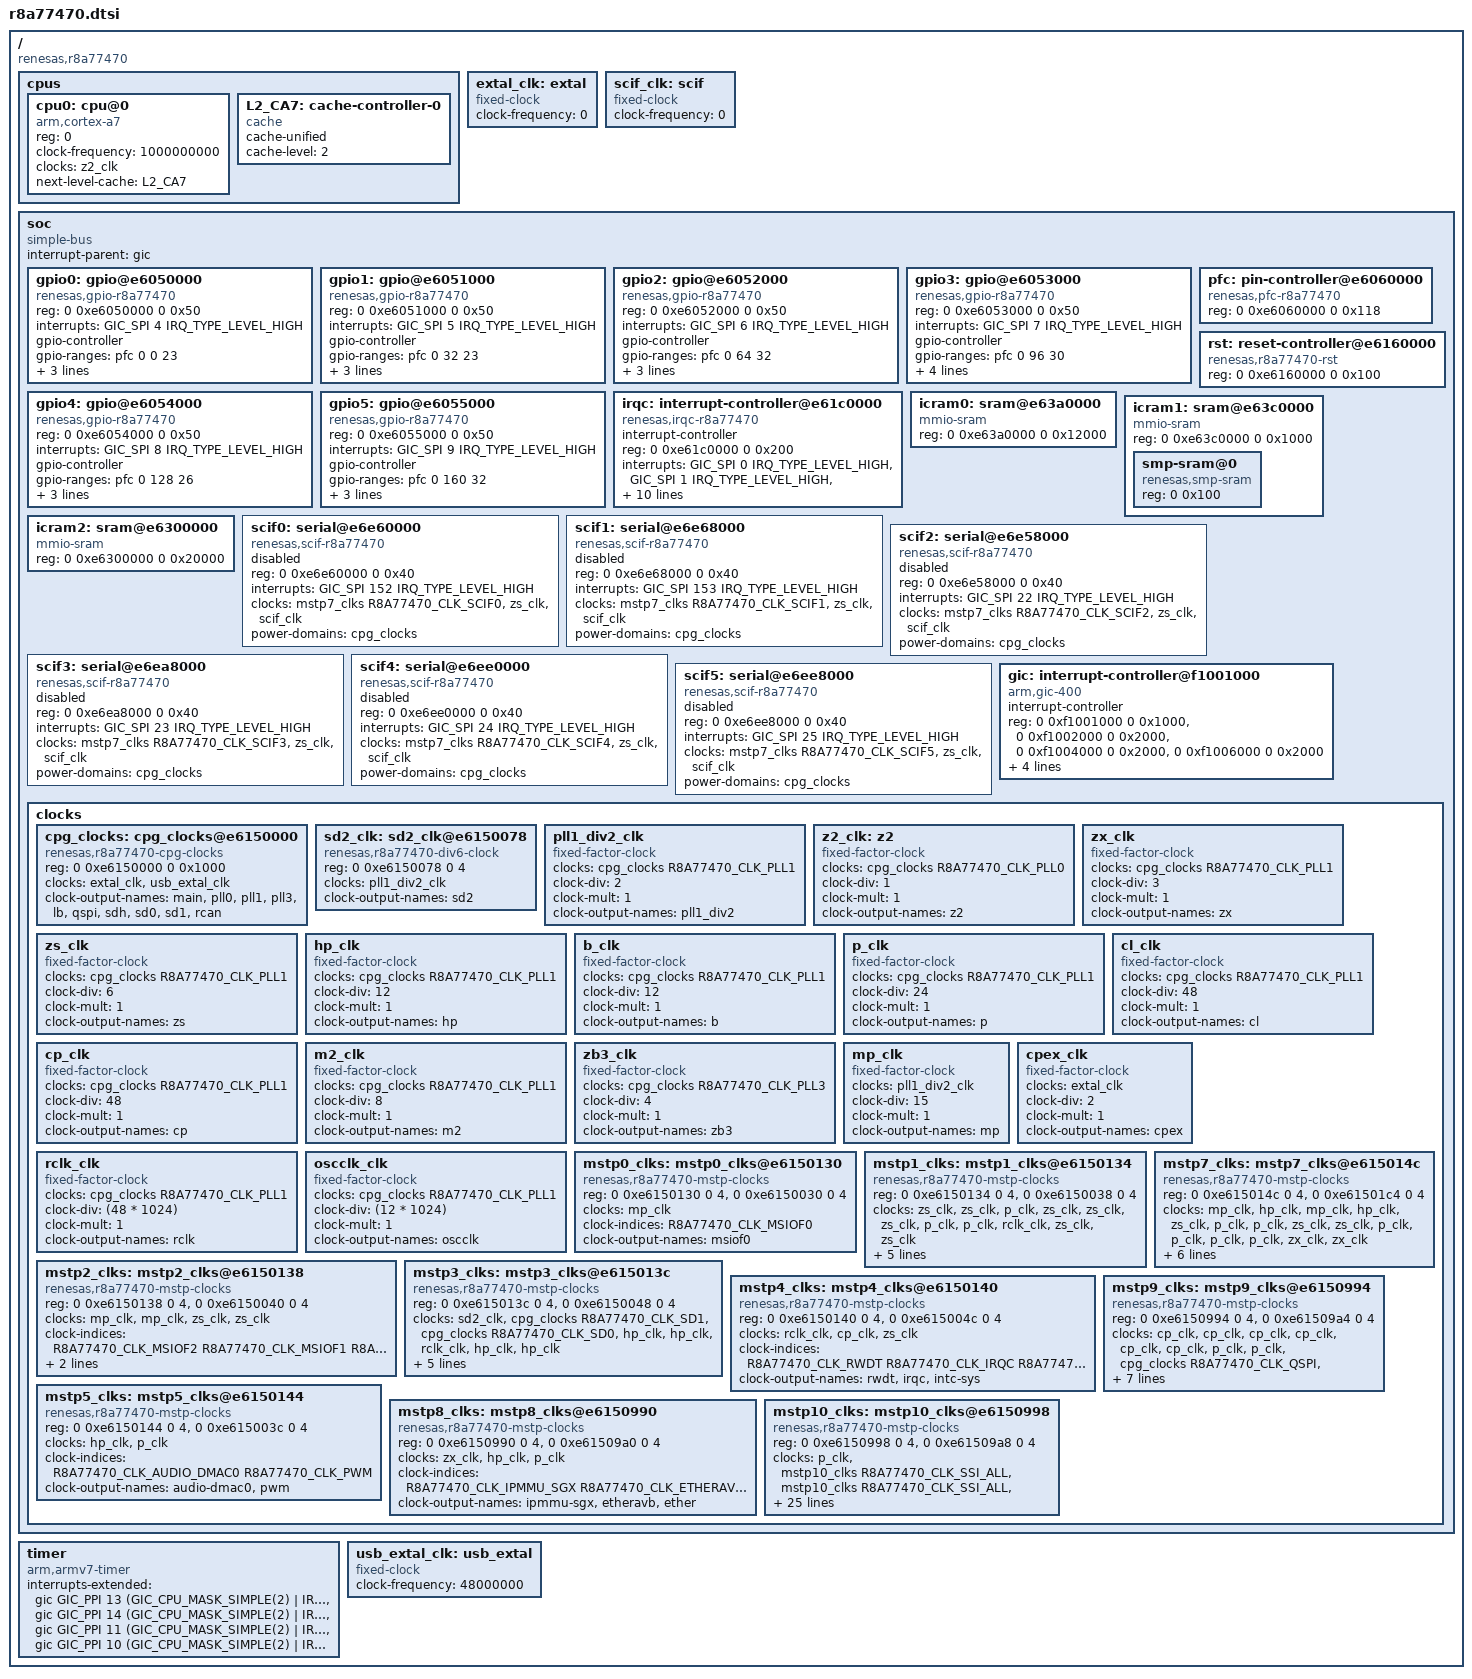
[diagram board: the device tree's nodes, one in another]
// SPDX-License-Identifier: GPL-2.0
/*
 * Device Tree Source for the r8a77470 SoC
 *
 * Copyright (C) 2018 Renesas Electronics Corp.
 */

#include <dt-bindings/interrupt-controller/irq.h>
#include <dt-bindings/interrupt-controller/arm-gic.h>
#include <dt-bindings/clock/r8a77470-clock.h>

/ {
	compatible = "renesas,r8a77470";
	#address-cells = <2>;
	#size-cells = <2>;

	cpus {
		#address-cells = <1>;
		#size-cells = <0>;

		cpu0: cpu@0 {
			device_type = "cpu";
			compatible = "arm,cortex-a7";
			reg = <0>;
			clock-frequency = <1000000000>;
			clocks = <&z2_clk>;
			next-level-cache = <&L2_CA7>;
		};


		L2_CA7: cache-controller-0 {
			compatible = "cache";
			cache-unified;
			cache-level = <2>;
		};
	};

	/* External root clock */
	extal_clk: extal {
		compatible = "fixed-clock";
		#clock-cells = <0>;
		/* This value must be overridden by the board. */
		clock-frequency = <0>;
	};

	/* External SCIF clock */
	scif_clk: scif {
		compatible = "fixed-clock";
		#clock-cells = <0>;
		/* This value must be overridden by the board. */
		clock-frequency = <0>;
	};

	soc {
		compatible = "simple-bus";
		interrupt-parent = <&gic>;

		#address-cells = <2>;
		#size-cells = <2>;
		ranges;

		gpio0: gpio@e6050000 {
			compatible = "renesas,gpio-r8a77470",
				     "renesas,rcar-gen2-gpio";
			reg = <0 0xe6050000 0 0x50>;
			interrupts = <GIC_SPI 4 IRQ_TYPE_LEVEL_HIGH>;
			#gpio-cells = <2>;
			gpio-controller;
			gpio-ranges = <&pfc 0 0 23>;
			#interrupt-cells = <2>;
			interrupt-controller;
			clocks = <&mstp9_clks R8A77470_CLK_GPIO0>;
			power-domains = <&cpg_clocks>;
		};

		gpio1: gpio@e6051000 {
			compatible = "renesas,gpio-r8a77470",
				     "renesas,rcar-gen2-gpio";
			reg = <0 0xe6051000 0 0x50>;
			interrupts = <GIC_SPI 5 IRQ_TYPE_LEVEL_HIGH>;
			#gpio-cells = <2>;
			gpio-controller;
			gpio-ranges = <&pfc 0 32 23>;
			#interrupt-cells = <2>;
			interrupt-controller;
			clocks = <&mstp9_clks R8A77470_CLK_GPIO1>;
			power-domains = <&cpg_clocks>;
		};

		gpio2: gpio@e6052000 {
			compatible = "renesas,gpio-r8a77470",
				     "renesas,rcar-gen2-gpio";
			reg = <0 0xe6052000 0 0x50>;
			interrupts = <GIC_SPI 6 IRQ_TYPE_LEVEL_HIGH>;
			#gpio-cells = <2>;
			gpio-controller;
			gpio-ranges = <&pfc 0 64 32>;
			#interrupt-cells = <2>;
			interrupt-controller;
			clocks = <&mstp9_clks R8A77470_CLK_GPIO2>;
			power-domains = <&cpg_clocks>;
		};

		gpio3: gpio@e6053000 {
			compatible = "renesas,gpio-r8a77470",
				     "renesas,rcar-gen2-gpio";
			reg = <0 0xe6053000 0 0x50>;
			interrupts = <GIC_SPI 7 IRQ_TYPE_LEVEL_HIGH>;
			#gpio-cells = <2>;
			gpio-controller;
			gpio-ranges = <&pfc 0 96 30>;
			gpio-reserved-ranges = <17 10>;
			#interrupt-cells = <2>;
			interrupt-controller;
			clocks = <&mstp9_clks R8A77470_CLK_GPIO3>;
			power-domains = <&cpg_clocks>;
		};

		gpio4: gpio@e6054000 {
			compatible = "renesas,gpio-r8a77470",
				     "renesas,rcar-gen2-gpio";
			reg = <0 0xe6054000 0 0x50>;
			interrupts = <GIC_SPI 8 IRQ_TYPE_LEVEL_HIGH>;
			#gpio-cells = <2>;
			gpio-controller;
			gpio-ranges = <&pfc 0 128 26>;
			#interrupt-cells = <2>;
			interrupt-controller;
			clocks = <&mstp9_clks R8A77470_CLK_GPIO4>;
			power-domains = <&cpg_clocks>;
		};

		gpio5: gpio@e6055000 {
			compatible = "renesas,gpio-r8a77470",
				     "renesas,rcar-gen2-gpio";
			reg = <0 0xe6055000 0 0x50>;
			interrupts = <GIC_SPI 9 IRQ_TYPE_LEVEL_HIGH>;
			#gpio-cells = <2>;
			gpio-controller;
			gpio-ranges = <&pfc 0 160 32>;
			#interrupt-cells = <2>;
			interrupt-controller;
			clocks = <&mstp9_clks R8A77470_CLK_GPIO5>;
			power-domains = <&cpg_clocks>;
		};

		pfc: pin-controller@e6060000 {
			compatible = "renesas,pfc-r8a77470";
			reg = <0 0xe6060000 0 0x118>;
		};

		rst: reset-controller@e6160000 {
			compatible = "renesas,r8a77470-rst";
			reg = <0 0xe6160000 0 0x100>;
		};

		irqc: interrupt-controller@e61c0000 {
			compatible = "renesas,irqc-r8a77470", "renesas,irqc";
			#interrupt-cells = <2>;
			interrupt-controller;
			reg = <0 0xe61c0000 0 0x200>;
			interrupts = <GIC_SPI 0 IRQ_TYPE_LEVEL_HIGH>,
				     <GIC_SPI 1 IRQ_TYPE_LEVEL_HIGH>,
				     <GIC_SPI 2 IRQ_TYPE_LEVEL_HIGH>,
				     <GIC_SPI 3 IRQ_TYPE_LEVEL_HIGH>,
				     <GIC_SPI 12 IRQ_TYPE_LEVEL_HIGH>,
				     <GIC_SPI 13 IRQ_TYPE_LEVEL_HIGH>,
				     <GIC_SPI 14 IRQ_TYPE_LEVEL_HIGH>,
				     <GIC_SPI 15 IRQ_TYPE_LEVEL_HIGH>,
				     <GIC_SPI 16 IRQ_TYPE_LEVEL_HIGH>,
				     <GIC_SPI 17 IRQ_TYPE_LEVEL_HIGH>;
			clocks = <&mstp4_clks R8A77470_CLK_IRQC>;
			power-domains = <&cpg_clocks>;
		};

		icram0:	sram@e63a0000 {
			compatible = "mmio-sram";
			reg = <0 0xe63a0000 0 0x12000>;
		};

		icram1:	sram@e63c0000 {
			compatible = "mmio-sram";
			reg = <0 0xe63c0000 0 0x1000>;
			#address-cells = <1>;
			#size-cells = <1>;
			ranges = <0 0 0xe63c0000 0x1000>;

			smp-sram@0 {
				compatible = "renesas,smp-sram";
				reg = <0 0x100>;
			};
		};

		icram2:	sram@e6300000 {
			compatible = "mmio-sram";
			reg = <0 0xe6300000 0 0x20000>;
		};

		scif0: serial@e6e60000 {
			compatible = "renesas,scif-r8a77470", "renesas,scif";
			reg = <0 0xe6e60000 0 0x40>;
			interrupts = <GIC_SPI 152 IRQ_TYPE_LEVEL_HIGH>;
			clocks = <&mstp7_clks R8A77470_CLK_SCIF0>,
				 <&zs_clk>, <&scif_clk>;
			clock-names = "sci_ick", "brg_int", "scif_clk";
			power-domains = <&cpg_clocks>;
			status = "disabled";
		};

		scif1: serial@e6e68000 {
			compatible = "renesas,scif-r8a77470", "renesas,scif";
			reg = <0 0xe6e68000 0 0x40>;
			interrupts = <GIC_SPI 153 IRQ_TYPE_LEVEL_HIGH>;
			clocks = <&mstp7_clks R8A77470_CLK_SCIF1>,
				 <&zs_clk>, <&scif_clk>;
			clock-names = "sci_ick", "brg_int", "scif_clk";
			power-domains = <&cpg_clocks>;
			status = "disabled";
		};

		scif2: serial@e6e58000 {
			compatible = "renesas,scif-r8a77470", "renesas,scif";
			reg = <0 0xe6e58000 0 0x40>;
			interrupts = <GIC_SPI 22 IRQ_TYPE_LEVEL_HIGH>;
			clocks = <&mstp7_clks R8A77470_CLK_SCIF2>,
				 <&zs_clk>, <&scif_clk>;
			clock-names = "sci_ick", "brg_int", "scif_clk";
			power-domains = <&cpg_clocks>;
			status = "disabled";
		};

		scif3: serial@e6ea8000 {
			compatible = "renesas,scif-r8a77470", "renesas,scif";
			reg = <0 0xe6ea8000 0 0x40>;
			interrupts = <GIC_SPI 23 IRQ_TYPE_LEVEL_HIGH>;
			clocks = <&mstp7_clks R8A77470_CLK_SCIF3>,
				 <&zs_clk>, <&scif_clk>;
			clock-names = "sci_ick", "brg_int", "scif_clk";
			power-domains = <&cpg_clocks>;
			status = "disabled";
		};

		scif4: serial@e6ee0000 {
			compatible = "renesas,scif-r8a77470", "renesas,scif";
			reg = <0 0xe6ee0000 0 0x40>;
			interrupts = <GIC_SPI 24 IRQ_TYPE_LEVEL_HIGH>;
			clocks = <&mstp7_clks R8A77470_CLK_SCIF4>,
				 <&zs_clk>, <&scif_clk>;
			clock-names = "sci_ick", "brg_int", "scif_clk";
			power-domains = <&cpg_clocks>;
			status = "disabled";
		};

		scif5: serial@e6ee8000 {
			compatible = "renesas,scif-r8a77470",
				     "renesas,rcar-gen2-scif", "renesas,scif";
			reg = <0 0xe6ee8000 0 0x40>;
			interrupts = <GIC_SPI 25 IRQ_TYPE_LEVEL_HIGH>;
			clocks = <&mstp7_clks R8A77470_CLK_SCIF5>,
				 <&zs_clk>, <&scif_clk>;
			clock-names = "sci_ick", "brg_int", "scif_clk";
			power-domains = <&cpg_clocks>;
			status = "disabled";
		};

		gic: interrupt-controller@f1001000 {
			compatible = "arm,gic-400";
			#interrupt-cells = <3>;
			#address-cells = <0>;
			interrupt-controller;
			reg = <0 0xf1001000 0 0x1000>, <0 0xf1002000 0 0x2000>,
			      <0 0xf1004000 0 0x2000>, <0 0xf1006000 0 0x2000>;
			interrupts = <GIC_PPI 9 (GIC_CPU_MASK_SIMPLE(2) | IRQ_TYPE_LEVEL_HIGH)>;
			clocks = <&mstp4_clks R8A77470_CLK_INTC_SYS>;
			clock-names = "clk";
			power-domains = <&cpg_clocks>;
		};

		clocks {
			#address-cells = <2>;
			#size-cells = <2>;
			ranges;

			/* Special CPG clocks */
			cpg_clocks: cpg_clocks@e6150000 {
				compatible = "renesas,r8a77470-cpg-clocks",
					     "renesas,rcar-gen2-cpg-clocks";
				reg = <0 0xe6150000 0 0x1000>;
				clocks = <&extal_clk &usb_extal_clk>;
				#clock-cells = <1>;
				clock-output-names = "main", "pll0", "pll1",
						     "pll3", "lb", "qspi",
						     "sdh", "sd0", "sd1",
						     "rcan";
				#power-domain-cells = <0>;
			};

			/* Variable factor clocks */
			sd2_clk: sd2_clk@e6150078 {
				compatible = "renesas,r8a77470-div6-clock",
					     "renesas,cpg-div6-clock";
				reg = <0 0xe6150078 0 4>;
				clocks = <&pll1_div2_clk>;
				#clock-cells = <0>;
				clock-output-names = "sd2";
			};

			/* Fixed factor clocks */
			pll1_div2_clk: pll1_div2_clk {
				compatible = "fixed-factor-clock";
				clocks = <&cpg_clocks R8A77470_CLK_PLL1>;
				#clock-cells = <0>;
				clock-div = <2>;
				clock-mult = <1>;
				clock-output-names = "pll1_div2";
			};
			z2_clk: z2 {
				compatible = "fixed-factor-clock";
				clocks = <&cpg_clocks R8A77470_CLK_PLL0>;
				#clock-cells = <0>;
				clock-div = <1>;
				clock-mult = <1>;
				clock-output-names = "z2";
			};
			zx_clk: zx_clk {
				compatible = "fixed-factor-clock";
				clocks = <&cpg_clocks R8A77470_CLK_PLL1>;
				#clock-cells = <0>;
				clock-div = <3>;
				clock-mult = <1>;
				clock-output-names = "zx";
			};
			zs_clk: zs_clk {
				compatible = "fixed-factor-clock";
				clocks = <&cpg_clocks R8A77470_CLK_PLL1>;
				#clock-cells = <0>;
				clock-div = <6>;
				clock-mult = <1>;
				clock-output-names = "zs";
			};
			hp_clk: hp_clk {
				compatible = "fixed-factor-clock";
				clocks = <&cpg_clocks R8A77470_CLK_PLL1>;
				#clock-cells = <0>;
				clock-div = <12>;
				clock-mult = <1>;
				clock-output-names = "hp";
			};
			b_clk: b_clk {
				compatible = "fixed-factor-clock";
				clocks = <&cpg_clocks R8A77470_CLK_PLL1>;
				#clock-cells = <0>;
				clock-div = <12>;
				clock-mult = <1>;
				clock-output-names = "b";
			};
			p_clk: p_clk {
				compatible = "fixed-factor-clock";
				clocks = <&cpg_clocks R8A77470_CLK_PLL1>;
				#clock-cells = <0>;
				clock-div = <24>;
				clock-mult = <1>;
				clock-output-names = "p";
			};
			cl_clk: cl_clk {
				compatible = "fixed-factor-clock";
				clocks = <&cpg_clocks R8A77470_CLK_PLL1>;
				#clock-cells = <0>;
				clock-div = <48>;
				clock-mult = <1>;
				clock-output-names = "cl";
			};
			cp_clk: cp_clk {
				compatible = "fixed-factor-clock";
				clocks = <&cpg_clocks R8A77470_CLK_PLL1>;
				#clock-cells = <0>;
				clock-div = <48>;
				clock-mult = <1>;
				clock-output-names = "cp";
			};
			m2_clk: m2_clk {
				compatible = "fixed-factor-clock";
				clocks = <&cpg_clocks R8A77470_CLK_PLL1>;
				#clock-cells = <0>;
				clock-div = <8>;
				clock-mult = <1>;
				clock-output-names = "m2";
			};
			zb3_clk: zb3_clk {
				compatible = "fixed-factor-clock";
				clocks = <&cpg_clocks R8A77470_CLK_PLL3>;
				#clock-cells = <0>;
				clock-div = <4>;
				clock-mult = <1>;
				clock-output-names = "zb3";
			};
			mp_clk: mp_clk {
				compatible = "fixed-factor-clock";
				clocks = <&pll1_div2_clk>;
				#clock-cells = <0>;
				clock-div = <15>;
				clock-mult = <1>;
				clock-output-names = "mp";
			};
			cpex_clk: cpex_clk {
				compatible = "fixed-factor-clock";
				clocks = <&extal_clk>;
				#clock-cells = <0>;
				clock-div = <2>;
				clock-mult = <1>;
				clock-output-names = "cpex";
			};
			rclk_clk: rclk_clk {
				compatible = "fixed-factor-clock";
				clocks = <&cpg_clocks R8A77470_CLK_PLL1>;
				#clock-cells = <0>;
				clock-div = <(48 * 1024)>;
				clock-mult = <1>;
				clock-output-names = "rclk";
			};
			oscclk_clk: oscclk_clk {
				compatible = "fixed-factor-clock";
				clocks = <&cpg_clocks R8A77470_CLK_PLL1>;
				#clock-cells = <0>;
				clock-div = <(12 * 1024)>;
				clock-mult = <1>;
				clock-output-names = "oscclk";
			};

			/* Gate clocks */
			mstp0_clks: mstp0_clks@e6150130 {
				compatible = "renesas,r8a77470-mstp-clocks",
					     "renesas,cpg-mstp-clocks";
				reg = <0 0xe6150130 0 4>, <0 0xe6150030 0 4>;
				clocks = <&mp_clk>;
				#clock-cells = <1>;
				clock-indices = <R8A77470_CLK_MSIOF0>;
				clock-output-names = "msiof0";
			};
			mstp1_clks: mstp1_clks@e6150134 {
				compatible = "renesas,r8a77470-mstp-clocks",
					     "renesas,cpg-mstp-clocks";
				reg = <0 0xe6150134 0 4>, <0 0xe6150038 0 4>;
				clocks = <&zs_clk>, <&zs_clk>, <&p_clk>,
					 <&zs_clk>, <&zs_clk>, <&zs_clk>,
					 <&p_clk>, <&p_clk>, <&rclk_clk>,
					 <&zs_clk>, <&zs_clk>;
				#clock-cells = <1>;
				clock-indices = <
					R8A77470_CLK_VCP0 R8A77470_CLK_VPC0
					R8A77470_CLK_TMU1 R8A77470_CLK_3DG
					R8A77470_CLK_2DDMAC R8A77470_CLK_FDP1_0
					R8A77470_CLK_TMU3 R8A77470_CLK_TMU2
					R8A77470_CLK_CMT0 R8A77470_CLK_VSP1DU0
					R8A77470_CLK_VSP1_SY
				>;
				clock-output-names =
					"vcp0", "vpc0", "tmu1",
					"3dg", "2d-dmac", "fdp1-0",
					"tmu3", "tmu2", "cmt0",
					"vsp1du0", "vsp1-sy";
			};
			mstp2_clks: mstp2_clks@e6150138 {
				compatible = "renesas,r8a77470-mstp-clocks",
					     "renesas,cpg-mstp-clocks";
				reg = <0 0xe6150138 0 4>, <0 0xe6150040 0 4>;
				clocks = <&mp_clk>, <&mp_clk>, <&zs_clk>,
					 <&zs_clk>;
				#clock-cells = <1>;
				clock-indices = <
					R8A77470_CLK_MSIOF2
					R8A77470_CLK_MSIOF1
					R8A77470_CLK_SYS_DMAC1
					R8A77470_CLK_SYS_DMAC0
				>;
				clock-output-names =
					"msiof2", "msiof1", "sys-dmac1",
					"sys-dmac0";
			};
			mstp3_clks: mstp3_clks@e615013c {
				compatible = "renesas,r8a77470-mstp-clocks",
					     "renesas,cpg-mstp-clocks";
				reg = <0 0xe615013c 0 4>, <0 0xe6150048 0 4>;
				clocks = <&sd2_clk>,
					 <&cpg_clocks R8A77470_CLK_SD1>,
					 <&cpg_clocks R8A77470_CLK_SD0>,
					 <&hp_clk>, <&hp_clk>, <&rclk_clk>,
					 <&hp_clk>, <&hp_clk>;
				#clock-cells = <1>;
				clock-indices = <
					R8A77470_CLK_SDHI2
					R8A77470_CLK_SDHI1
					R8A77470_CLK_SDHI0
					R8A77470_CLK_USBHS_DMAC0_CH1
					R8A77470_CLK_USBHS_DMAC1_CH1
					R8A77470_CLK_CMT1
					R8A77470_CLK_USBHS_DMAC0_CH0
					R8A77470_CLK_USBHS_DMAC1_CH0
				>;
				clock-output-names =
					"sdhi2", "sdhi1", "sdhi0",
					"usbhs-dmac0-ch1", "usbhs-dmac1-ch1",
					"cmt1", "usbhs-dmac0-ch0",
					"usbhs-dmac1-ch0";
			};
			mstp4_clks: mstp4_clks@e6150140 {
				compatible = "renesas,r8a77470-mstp-clocks",
					     "renesas,cpg-mstp-clocks";
				reg = <0 0xe6150140 0 4>, <0 0xe615004c 0 4>;
				clocks = <&rclk_clk>, <&cp_clk>, <&zs_clk>;
				#clock-cells = <1>;
				clock-indices = <
					R8A77470_CLK_RWDT R8A77470_CLK_IRQC
					R8A77470_CLK_INTC_SYS
				>;
				clock-output-names = "rwdt", "irqc", "intc-sys";
			};
			mstp5_clks: mstp5_clks@e6150144 {
				compatible = "renesas,r8a77470-mstp-clocks",
					     "renesas,cpg-mstp-clocks";
				reg = <0 0xe6150144 0 4>, <0 0xe615003c 0 4>;
				clocks = <&hp_clk>, <&p_clk>;
				#clock-cells = <1>;
				clock-indices = <
					R8A77470_CLK_AUDIO_DMAC0
					R8A77470_CLK_PWM
				>;
				clock-output-names = "audio-dmac0", "pwm";
			};
			mstp7_clks: mstp7_clks@e615014c {
				compatible = "renesas,r8a77470-mstp-clocks",
					     "renesas,cpg-mstp-clocks";
				reg = <0 0xe615014c 0 4>, <0 0xe61501c4 0 4>;
				clocks = <&mp_clk>, <&hp_clk>, <&mp_clk>,
					 <&hp_clk>, <&zs_clk>, <&p_clk>,
					 <&p_clk>, <&zs_clk>, <&zs_clk>,
					 <&p_clk>, <&p_clk>, <&p_clk>,
					 <&p_clk>, <&zx_clk>, <&zx_clk>;
				#clock-cells = <1>;
				clock-indices = <
					R8A77470_CLK_USB_EHCI_0
					R8A77470_CLK_USBHS0
					R8A77470_CLK_USB_EHCI_1
					R8A77470_CLK_USBHS1 R8A77470_CLK_HSCIF2
					R8A77470_CLK_SCIF5 R8A77470_CLK_SCIF4
					R8A77470_CLK_HSCIF1 R8A77470_CLK_HSCIF0
					R8A77470_CLK_SCIF3 R8A77470_CLK_SCIF2
					R8A77470_CLK_SCIF1 R8A77470_CLK_SCIF0
					R8A77470_CLK_DU1 R8A77470_CLK_DU0
				>;
				clock-output-names =
					"usb-ehci-0", "usbhs-0", "usb-ehci-1",
					"usbhs-1", "hscif2", "scif5", "scif4",
					"hscif1", "hscif0", "scif3", "scif2",
					"scif1", "scif0", "du1", "du0";
			};
			mstp8_clks: mstp8_clks@e6150990 {
				compatible = "renesas,r8a77470-mstp-clocks",
					     "renesas,cpg-mstp-clocks";
				reg = <0 0xe6150990 0 4>, <0 0xe61509a0 0 4>;
				clocks = <&zx_clk>, <&hp_clk>, <&p_clk>;
				#clock-cells = <1>;
				clock-indices = <
					R8A77470_CLK_IPMMU_SGX
					R8A77470_CLK_ETHERAVB R8A77470_CLK_ETHER
				>;
				clock-output-names =
					"ipmmu-sgx", "etheravb", "ether";
			};
			mstp9_clks: mstp9_clks@e6150994 {
				compatible = "renesas,r8a77470-mstp-clocks",
					     "renesas,cpg-mstp-clocks";
				reg = <0 0xe6150994 0 4>, <0 0xe61509a4 0 4>;
				clocks = <&cp_clk>, <&cp_clk>, <&cp_clk>,
					 <&cp_clk>, <&cp_clk>, <&cp_clk>,
					 <&p_clk>, <&p_clk>,
					 <&cpg_clocks R8A77470_CLK_QSPI>,
					 <&cpg_clocks R8A77470_CLK_QSPI>,
					 <&hp_clk>, <&hp_clk>, <&hp_clk>,
					 <&hp_clk>, <&hp_clk>;
				#clock-cells = <1>;
				clock-indices = <
					R8A77470_CLK_GPIO5 R8A77470_CLK_GPIO4
					R8A77470_CLK_GPIO3 R8A77470_CLK_GPIO2
					R8A77470_CLK_GPIO1 R8A77470_CLK_GPIO0
					R8A77470_CLK_CAN1 R8A77470_CLK_CAN0
					R8A77470_CLK_QUAD_SPI1
					R8A77470_CLK_QUAD_SPI0
					R8A77470_CLK_I2C4 R8A77470_CLK_I2C3
					R8A77470_CLK_I2C2 R8A77470_CLK_I2C1
					R8A77470_CLK_I2C0
				>;
				clock-output-names =
					"gpio5", "gpio4", "gpio3", "gpio2",
					"gpio1", "gpio0", "can1", "can0",
					"qspi_mod-1", "qspi_mod-0", "i2c4",
					"i2c3", "i2c2", "i2c1", "i2c0";
			};
			mstp10_clks: mstp10_clks@e6150998 {
				compatible = "renesas,r8a77470-mstp-clocks",
					     "renesas,cpg-mstp-clocks";
				reg = <0 0xe6150998 0 4>, <0 0xe61509a8 0 4>;
				clocks = <&p_clk>,
					 <&mstp10_clks R8A77470_CLK_SSI_ALL>,
					 <&mstp10_clks R8A77470_CLK_SSI_ALL>,
					 <&mstp10_clks R8A77470_CLK_SSI_ALL>,
					 <&mstp10_clks R8A77470_CLK_SSI_ALL>,
					 <&mstp10_clks R8A77470_CLK_SSI_ALL>,
					 <&mstp10_clks R8A77470_CLK_SSI_ALL>,
					 <&mstp10_clks R8A77470_CLK_SSI_ALL>,
					 <&mstp10_clks R8A77470_CLK_SSI_ALL>,
					 <&mstp10_clks R8A77470_CLK_SSI_ALL>,
					 <&mstp10_clks R8A77470_CLK_SSI_ALL>,
					 <&p_clk>,
					 <&mstp10_clks R8A77470_CLK_SCU_ALL>,
					 <&mstp10_clks R8A77470_CLK_SCU_ALL>,
					 <&mstp10_clks R8A77470_CLK_SCU_ALL>,
					 <&mstp10_clks R8A77470_CLK_SCU_ALL>,
					 <&mstp10_clks R8A77470_CLK_SCU_ALL>,
					 <&mstp10_clks R8A77470_CLK_SCU_ALL>,
					 <&mstp10_clks R8A77470_CLK_SCU_ALL>,
					 <&mstp10_clks R8A77470_CLK_SCU_ALL>,
					 <&mstp10_clks R8A77470_CLK_SCU_ALL>,
					 <&mstp10_clks R8A77470_CLK_SCU_ALL>;
				#clock-cells = <1>;
				clock-indices = <
					R8A77470_CLK_SSI_ALL R8A77470_CLK_SSI9
					R8A77470_CLK_SSI8 R8A77470_CLK_SSI7
					R8A77470_CLK_SSI6 R8A77470_CLK_SSI5
					R8A77470_CLK_SSI4 R8A77470_CLK_SSI3
					R8A77470_CLK_SSI2 R8A77470_CLK_SSI1
					R8A77470_CLK_SSI0 R8A77470_CLK_SCU_ALL
					R8A77470_CLK_SCU_DVC1
					R8A77470_CLK_SCU_DVC0
					R8A77470_CLK_SCU_CTU1_MIX1
					R8A77470_CLK_SCU_CTU0_MIX0
					R8A77470_CLK_SCU_SRC6
					R8A77470_CLK_SCU_SRC5
					R8A77470_CLK_SCU_SRC4
					R8A77470_CLK_SCU_SRC3
					R8A77470_CLK_SCU_SRC2
					R8A77470_CLK_SCU_SRC1
				>;
				clock-output-names =
					"ssi-all", "ssi9", "ssi8", "ssi7",
					"ssi6",	"ssi5",	"ssi4",	"ssi3",	"ssi2",
					"ssi1",	"ssi0",	"scu-all", "scu-dvc1",
					"scu-dvc0", "scu-ctu1-mix1",
					"scu-ctu0-mix0", "scu-src6", "scu-src5",
					"scu-src4", "scu-src3", "scu-src2",
					"scu-src1";
			};
		};
	};

	timer {
		compatible = "arm,armv7-timer";
		interrupts-extended = <&gic GIC_PPI 13 (GIC_CPU_MASK_SIMPLE(2) | IRQ_TYPE_LEVEL_LOW)>,
				      <&gic GIC_PPI 14 (GIC_CPU_MASK_SIMPLE(2) | IRQ_TYPE_LEVEL_LOW)>,
				      <&gic GIC_PPI 11 (GIC_CPU_MASK_SIMPLE(2) | IRQ_TYPE_LEVEL_LOW)>,
				      <&gic GIC_PPI 10 (GIC_CPU_MASK_SIMPLE(2) | IRQ_TYPE_LEVEL_LOW)>;
	};

	/* External USB clock - can be overridden by the board */
	usb_extal_clk: usb_extal {
		compatible = "fixed-clock";
		#clock-cells = <0>;
		clock-frequency = <48000000>;
	};
};
